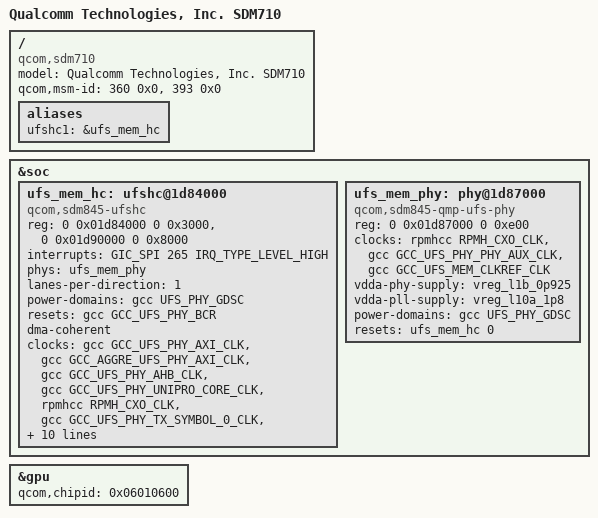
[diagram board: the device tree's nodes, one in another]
// SPDX-License-Identifier: GPL-2.0-only
/*
 * SDM710 SoC description for the Linux mainline recovery kernel.
 *
 * Linux models SDM710 through the SDM670 SoC description. The UFS block is
 * added here because upstream SDM670 currently only describes the SDHC path,
 * while the RMX1901 vendor DTB exposes UFS at the same controller address.
 */

#include "sdm670.dtsi"

/ {
	model = "Qualcomm Technologies, Inc. SDM710";
	compatible = "qcom,sdm710", "qcom,sdm670";
	qcom,msm-id = <360 0x0>, <393 0x0>;

	aliases {
		ufshc1 = &ufs_mem_hc;
	};
};

&soc {
	ufs_mem_hc: ufshc@1d84000 {
		compatible = "qcom,sdm845-ufshc", "qcom,ufshc",
				     "jedec,ufs-2.0";
		reg = <0 0x01d84000 0 0x3000>,
		      <0 0x01d90000 0 0x8000>;
		reg-names = "std", "ice";
		interrupts = <GIC_SPI 265 IRQ_TYPE_LEVEL_HIGH>;
		phys = <&ufs_mem_phy>;
		phy-names = "ufsphy";
		lanes-per-direction = <1>;
		power-domains = <&gcc UFS_PHY_GDSC>;
		#reset-cells = <1>;
		resets = <&gcc GCC_UFS_PHY_BCR>;
		reset-names = "rst";
		dma-coherent;

		clock-names = "core_clk",
			      "bus_aggr_clk",
			      "iface_clk",
			      "core_clk_unipro",
			      "ref_clk",
			      "tx_lane0_sync_clk",
			      "rx_lane0_sync_clk",
			      "rx_lane1_sync_clk",
			      "ice_core_clk";
		clocks = <&gcc GCC_UFS_PHY_AXI_CLK>,
			 <&gcc GCC_AGGRE_UFS_PHY_AXI_CLK>,
			 <&gcc GCC_UFS_PHY_AHB_CLK>,
			 <&gcc GCC_UFS_PHY_UNIPRO_CORE_CLK>,
			 <&rpmhcc RPMH_CXO_CLK>,
			 <&gcc GCC_UFS_PHY_TX_SYMBOL_0_CLK>,
			 <&gcc GCC_UFS_PHY_RX_SYMBOL_0_CLK>,
			 <&gcc GCC_UFS_PHY_RX_SYMBOL_1_CLK>,
			 <&gcc GCC_UFS_PHY_ICE_CORE_CLK>;
		freq-table-hz = <50000000 300000000>,
				<0 0>,
				<0 0>,
				<37500000 150000000>,
				<0 0>,
				<0 0>,
				<0 0>,
				<0 0>,
				<75000000 300000000>;

		interconnects = <&aggre1_noc MASTER_UFS_MEM 0
				 &mem_noc SLAVE_EBI_CH0 0>,
				<&gladiator_noc MASTER_AMPSS_M0 0
				 &config_noc SLAVE_UFS_MEM_CFG 0>;
		interconnect-names = "ufs-ddr", "cpu-ufs";

		status = "okay";
	};

	ufs_mem_phy: phy@1d87000 {
		compatible = "qcom,sdm845-qmp-ufs-phy";
		reg = <0 0x01d87000 0 0xe00>;

		clocks = <&rpmhcc RPMH_CXO_CLK>,
			 <&gcc GCC_UFS_PHY_PHY_AUX_CLK>,
			 <&gcc GCC_UFS_MEM_CLKREF_CLK>;
		clock-names = "ref", "ref_aux", "qref";

		vdda-phy-supply = <&vreg_l1b_0p925>;
		vdda-pll-supply = <&vreg_l10a_1p8>;
		power-domains = <&gcc UFS_PHY_GDSC>;
		resets = <&ufs_mem_hc 0>;
		reset-names = "ufsphy";

		#phy-cells = <0>;
		status = "okay";
	};
};

&gpu {
	qcom,chipid = <0x06010600>;
};
